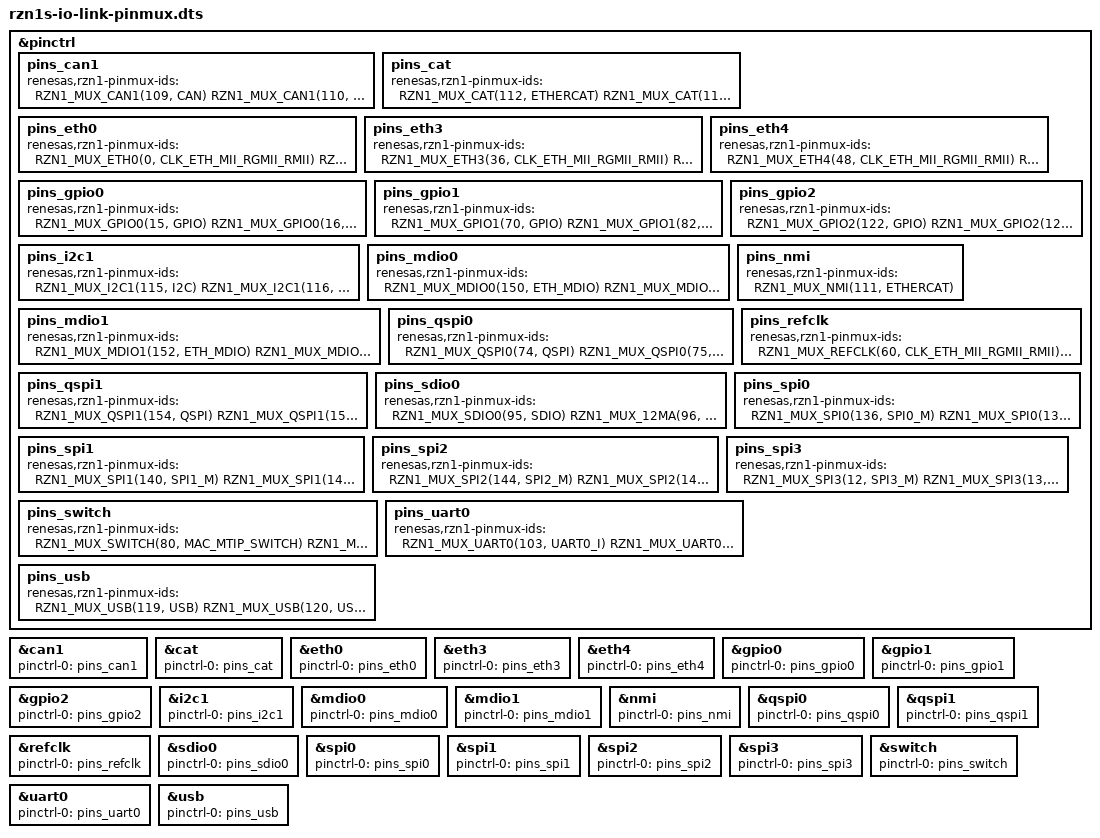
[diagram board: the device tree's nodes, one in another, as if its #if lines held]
/*
 * This file was autogenerated
 * DO NOT EDIT
 * (C) 2015-2016 Renesas Electronics Europe, LTD
 * All rights reserved.
 *
 * Redistribution and use in source and binary forms, with or without
 * modification, are permitted provided that the following conditions are met:
 *
 * 1. Redistributions of source code must retain the above copyright notice,
 * this list of conditions and the following disclaimer.
 *
 * 2. Redistributions in binary form must reproduce the above copyright notice,
 * this list of conditions and the following disclaimer in the documentation
 * and/or other materials provided with the distribution.
 *
 * THIS SOFTWARE IS PROVIDED BY THE COPYRIGHT HOLDERS AND CONTRIBUTORS "AS IS"
 * AND ANY EXPRESS OR IMPLIED WARRANTIES, INCLUDING, BUT NOT LIMITED TO, THE
 * IMPLIED WARRANTIES OF MERCHANTABILITY AND FITNESS FOR A PARTICULAR PURPOSE
 * ARE DISCLAIMED. IN NO EVENT SHALL THE COPYRIGHT HOLDER OR CONTRIBUTORS BE
 * LIABLE FOR ANY DIRECT, INDIRECT, INCIDENTAL, SPECIAL, EXEMPLARY, OR
 * CONSEQUENTIAL DAMAGES (INCLUDING, BUT NOT LIMITED TO, PROCUREMENT OF
 * SUBSTITUTE GOODS OR SERVICES; LOSS OF USE, DATA, OR PROFITS; OR BUSINESS
 * INTERRUPTION) HOWEVER CAUSED AND ON ANY THEORY OF LIABILITY, WHETHER IN
 * CONTRACT, STRICT LIABILITY, OR TORT (INCLUDING NEGLIGENCE OR OTHERWISE)
 * ARISING IN ANY WAY OUT OF THE USE OF THIS SOFTWARE, EVEN IF ADVISED OF THE
 * POSSIBILITY OF SUCH DAMAGE.
 */

#include "rzn1.dtsi"

/*
 * AUTOGENERATED DO NOT EDIT
 *
 * Renesas RZ/N1S IO Link Board
 * This file only sets the pin function by default.
 *
 * You can override the default mux pullup/down and drive by
 * defining the following macros in the board file before
 * including this.
 */

#ifndef RZN1_MUX_DEFAULT
#define RZN1_MUX_DEFAULT RZN1_MUX
#endif

#ifndef RZN1_MUX_CAN
#define RZN1_MUX_CAN RZN1_MUX_DEFAULT
#endif
#ifndef RZN1_MUX_CAN1
#define RZN1_MUX_CAN1 RZN1_MUX_CAN
#endif
#ifndef RZN1_MUX_CAT
#define RZN1_MUX_CAT RZN1_MUX_DEFAULT
#endif
#ifndef RZN1_MUX_ETH0
#define RZN1_MUX_ETH0 RZN1_MUX_PNONE_6MA
#endif
#ifndef RZN1_MUX_ETH3
#define RZN1_MUX_ETH3 RZN1_MUX_PNONE_6MA
#endif
#ifndef RZN1_MUX_ETH4
#define RZN1_MUX_ETH4 RZN1_MUX_PNONE_6MA
#endif
#ifndef RZN1_MUX_GPIO
#define RZN1_MUX_GPIO RZN1_MUX_DEFAULT
#endif
#ifndef RZN1_MUX_GPIO0
#define RZN1_MUX_GPIO0 RZN1_MUX_GPIO
#endif
#ifndef RZN1_MUX_GPIO1
#define RZN1_MUX_GPIO1 RZN1_MUX_GPIO
#endif
#ifndef RZN1_MUX_GPIO2
#define RZN1_MUX_GPIO2 RZN1_MUX_GPIO
#endif
#ifndef RZN1_MUX_I2C1
#define RZN1_MUX_I2C1 RZN1_MUX_12MA
#endif
#ifndef RZN1_MUX_MDIO
#define RZN1_MUX_MDIO RZN1_MUX_DEFAULT
#endif
#ifndef RZN1_MUX_MDIO0
#define RZN1_MUX_MDIO0 RZN1_MUX_MDIO
#endif
#ifndef RZN1_MUX_MDIO1
#define RZN1_MUX_MDIO1 RZN1_MUX_MDIO
#endif
#ifndef RZN1_MUX_NMI
#define RZN1_MUX_NMI RZN1_MUX_DEFAULT
#endif
#ifndef RZN1_MUX_QSPI
#define RZN1_MUX_QSPI RZN1_MUX_DEFAULT
#endif
#ifndef RZN1_MUX_QSPI0
#define RZN1_MUX_QSPI0 RZN1_MUX_QSPI
#endif
#ifndef RZN1_MUX_QSPI1
#define RZN1_MUX_QSPI1 RZN1_MUX_QSPI
#endif
#ifndef RZN1_MUX_REFCLK
#define RZN1_MUX_REFCLK RZN1_MUX_PNONE_6MA
#endif
#ifndef RZN1_MUX_SDIO
#define RZN1_MUX_SDIO RZN1_MUX_DEFAULT
#endif
#ifndef RZN1_MUX_SDIO0
#define RZN1_MUX_SDIO0 RZN1_MUX_SDIO
#endif
#ifndef RZN1_MUX_SPI
#define RZN1_MUX_SPI RZN1_MUX_DEFAULT
#endif
#ifndef RZN1_MUX_SPI0
#define RZN1_MUX_SPI0 RZN1_MUX_SPI
#endif
#ifndef RZN1_MUX_SPI1
#define RZN1_MUX_SPI1 RZN1_MUX_SPI
#endif
#ifndef RZN1_MUX_SPI2
#define RZN1_MUX_SPI2 RZN1_MUX_SPI
#endif
#ifndef RZN1_MUX_SPI3
#define RZN1_MUX_SPI3 RZN1_MUX_SPI
#endif
#ifndef RZN1_MUX_SWITCH
#define RZN1_MUX_SWITCH RZN1_MUX_DEFAULT
#endif
#ifndef RZN1_MUX_UART
#define RZN1_MUX_UART RZN1_MUX_DEFAULT
#endif
#ifndef RZN1_MUX_UART0
#define RZN1_MUX_UART0 RZN1_MUX_UART
#endif
#ifndef RZN1_MUX_USB
#define RZN1_MUX_USB RZN1_MUX_DEFAULT
#endif

&pinctrl {
	pins_can1: pins_can1 {
		renesas,rzn1-pinmux-ids = <
			RZN1_MUX_CAN1(109, CAN)		/* CAN1_TXD */
			RZN1_MUX_CAN1(110, CAN)		/* CAN1_RXD */
		>;
	};
	pins_cat: pins_cat {
		renesas,rzn1-pinmux-ids = <
			RZN1_MUX_CAT(112, ETHERCAT)	/* CAT_I2CDATA */
			RZN1_MUX_CAT(113, ETHERCAT)	/* CAT_I2CCLK */
		>;
	};
	pins_eth0: pins_eth0 {
		renesas,rzn1-pinmux-ids = <
			RZN1_MUX_ETH0(0, CLK_ETH_MII_RGMII_RMII)	/* ETH0_TXCLK */
			RZN1_MUX_ETH0(1, CLK_ETH_MII_RGMII_RMII)	/* ETH0_TXD[0] */
			RZN1_MUX_ETH0(2, CLK_ETH_MII_RGMII_RMII)	/* ETH0_TXD[1] */
			RZN1_MUX_ETH0(3, CLK_ETH_MII_RGMII_RMII)	/* ETH0_TXD[2] */
			RZN1_MUX_ETH0(4, CLK_ETH_MII_RGMII_RMII)	/* ETH0_TXD[3] */
			RZN1_MUX_ETH0(5, CLK_ETH_MII_RGMII_RMII)	/* ETH0_TXEN */
			RZN1_MUX_ETH0(6, CLK_ETH_MII_RGMII_RMII)	/* ETH0_RXCLK */
			RZN1_MUX_ETH0(7, CLK_ETH_MII_RGMII_RMII)	/* ETH0_RXD[0] */
			RZN1_MUX_ETH0(8, CLK_ETH_MII_RGMII_RMII)	/* ETH0_RXD[1] */
			RZN1_MUX_ETH0(9, CLK_ETH_MII_RGMII_RMII)	/* ETH0_RXD[2] */
			RZN1_MUX_ETH0(10, CLK_ETH_MII_RGMII_RMII)	/* ETH0_RXD[3] */
			RZN1_MUX_ETH0(11, CLK_ETH_MII_RGMII_RMII)	/* ETH0_RXDV */
		>;
	};
	pins_eth3: pins_eth3 {
		renesas,rzn1-pinmux-ids = <
			RZN1_MUX_ETH3(36, CLK_ETH_MII_RGMII_RMII)	/* ETH3_TXCLK */
			RZN1_MUX_ETH3(37, CLK_ETH_MII_RGMII_RMII)	/* ETH3_TXD[0] */
			RZN1_MUX_ETH3(38, CLK_ETH_MII_RGMII_RMII)	/* ETH3_TXD[1] */
			RZN1_MUX_ETH3(39, CLK_ETH_MII_RGMII_RMII)	/* ETH3_TXD[2] */
			RZN1_MUX_ETH3(40, CLK_ETH_MII_RGMII_RMII)	/* ETH3_TXD[3] */
			RZN1_MUX_ETH3(41, CLK_ETH_MII_RGMII_RMII)	/* ETH3_TXEN */
			RZN1_MUX_ETH3(42, CLK_ETH_MII_RGMII_RMII)	/* ETH3_RXCLK */
			RZN1_MUX_ETH3(43, CLK_ETH_MII_RGMII_RMII)	/* ETH3_RXD[0] */
			RZN1_MUX_ETH3(44, CLK_ETH_MII_RGMII_RMII)	/* ETH3_RXD[1] */
			RZN1_MUX_ETH3(45, CLK_ETH_MII_RGMII_RMII)	/* ETH3_RXD[2] */
			RZN1_MUX_ETH3(46, CLK_ETH_MII_RGMII_RMII)	/* ETH3_RXD[3] */
			RZN1_MUX_ETH3(47, CLK_ETH_MII_RGMII_RMII)	/* ETH3_RXDV */
			RZN1_MUX_ETH3(67, CLK_ETH_MII_RGMII_RMII)	/* ETH3_RXER */
			RZN1_MUX_ETH3(68, CLK_ETH_MII_RGMII_RMII)	/* ETH3_CRS */
			RZN1_MUX_ETH3(69, CLK_ETH_MII_RGMII_RMII)	/* ETH3_COL */
		>;
	};
	pins_eth4: pins_eth4 {
		renesas,rzn1-pinmux-ids = <
			RZN1_MUX_ETH4(48, CLK_ETH_MII_RGMII_RMII)	/* ETH4_TXCLK */
			RZN1_MUX_ETH4(49, CLK_ETH_MII_RGMII_RMII)	/* ETH4_TXD[0] */
			RZN1_MUX_ETH4(50, CLK_ETH_MII_RGMII_RMII)	/* ETH4_TXD[1] */
			RZN1_MUX_ETH4(51, CLK_ETH_MII_RGMII_RMII)	/* ETH4_TXD[2] */
			RZN1_MUX_ETH4(52, CLK_ETH_MII_RGMII_RMII)	/* ETH4_TXD[3] */
			RZN1_MUX_ETH4(53, CLK_ETH_MII_RGMII_RMII)	/* ETH4_TXEN */
			RZN1_MUX_ETH4(54, CLK_ETH_MII_RGMII_RMII)	/* ETH4_RXCLK */
			RZN1_MUX_ETH4(55, CLK_ETH_MII_RGMII_RMII)	/* ETH4_RXD[0] */
			RZN1_MUX_ETH4(56, CLK_ETH_MII_RGMII_RMII)	/* ETH4_RXD[1] */
			RZN1_MUX_ETH4(57, CLK_ETH_MII_RGMII_RMII)	/* ETH4_RXD[2] */
			RZN1_MUX_ETH4(58, CLK_ETH_MII_RGMII_RMII)	/* ETH4_RXD[3] */
			RZN1_MUX_ETH4(59, CLK_ETH_MII_RGMII_RMII)	/* ETH4_RXDV */
			RZN1_MUX_ETH4(71, CLK_ETH_MII_RGMII_RMII)	/* ETH4_RXER */
			RZN1_MUX_ETH4(72, CLK_ETH_MII_RGMII_RMII)	/* ETH4_CRS */
			RZN1_MUX_ETH4(73, CLK_ETH_MII_RGMII_RMII)	/* ETH4_COL */
		>;
	};
	pins_gpio0: pins_gpio0 {
		renesas,rzn1-pinmux-ids = <
			RZN1_MUX_GPIO0(15, GPIO)	/* GPIO0A[6] */
			RZN1_MUX_GPIO0(16, GPIO)	/* GPIO0A[7] */
			RZN1_MUX_GPIO0(19, GPIO)	/* GPIO0B[11] */
			RZN1_MUX_GPIO0(20, GPIO)	/* GPIO0B[12] */
			RZN1_MUX_GPIO0(21, GPIO)	/* GPIO0A[8] */
			RZN1_MUX_GPIO0(22, GPIO)	/* GPIO0A[9] */
			RZN1_MUX_GPIO0(23, GPIO)	/* GPIO0B[13] */
			RZN1_MUX_GPIO0(24, GPIO)	/* GPIO0A[10] */
			RZN1_MUX_GPIO0(25, GPIO)	/* GPIO0B[14] */
			RZN1_MUX_GPIO0(26, GPIO)	/* GPIO0B[15] */
			RZN1_MUX_GPIO0(27, GPIO)	/* GPIO0A[11] */
			RZN1_MUX_GPIO0(28, GPIO)	/* GPIO0A[12] */
			RZN1_MUX_GPIO0(33, GPIO)	/* GPIO0A[13] */
			RZN1_MUX_GPIO0(34, GPIO)	/* GPIO0A[14] */
			RZN1_MUX_GPIO0(35, GPIO)	/* GPIO0B[20] */
			RZN1_MUX_GPIO0(62, GPIO)	/* GPIO0A[25] */
			RZN1_MUX_GPIO0(63, GPIO)	/* GPIO0A[26] */
			RZN1_MUX_GPIO0(64, GPIO)	/* GPIO0A[27] */
			RZN1_MUX_GPIO0(65, GPIO)	/* GPIO0A[28] */
			RZN1_MUX_GPIO0(66, GPIO)	/* GPIO0A[29] */
		>;
	};
	pins_gpio1: pins_gpio1 {
		renesas,rzn1-pinmux-ids = <
			RZN1_MUX_GPIO1(70, GPIO)	/* GPIO1A[1] */
			RZN1_MUX_GPIO1(82, GPIO)	/* GPIO1B[13] */
			RZN1_MUX_GPIO1(83, GPIO)	/* GPIO1B[14] */
			RZN1_MUX_GPIO1(84, GPIO)	/* GPIO1B[15] */
			RZN1_MUX_GPIO1(85, GPIO)	/* GPIO1B[16] */
			RZN1_MUX_GPIO1(86, GPIO)	/* GPIO1B[17] */
			RZN1_MUX_GPIO1(87, GPIO)	/* GPIO1B[18] */
			RZN1_MUX_GPIO1(88, GPIO)	/* GPIO1B[19] */
			RZN1_MUX_GPIO1(89, GPIO)	/* GPIO1B[20] */
			RZN1_MUX_GPIO1(90, GPIO)	/* GPIO1B[21] */
			RZN1_MUX_GPIO1(91, GPIO)	/* GPIO1B[22] */
			RZN1_MUX_GPIO1(92, GPIO)	/* GPIO1B[23] */
			RZN1_MUX_GPIO1(93, GPIO)	/* GPIO1B[24] */
			RZN1_MUX_GPIO1(94, GPIO)	/* Eth PHY Reset (GPIO1B[25]) */
			RZN1_MUX_GPIO1(105, GPIO)	/* GPIO1A[15] */
			RZN1_MUX_GPIO1(106, GPIO)	/* GPIO1A[16] */
			RZN1_MUX_GPIO1(117, GPIO)	/* GPIO1A[27] */
			RZN1_MUX_GPIO1(118, GPIO)	/* Eth3 IRQ (GPIO1A[28]) */
			RZN1_MUX_GPIO1(121, GPIO)	/* GPIO1A[31] */
		>;
	};
	pins_gpio2: pins_gpio2 {
		renesas,rzn1-pinmux-ids = <
			RZN1_MUX_GPIO2(122, GPIO)	/* GPIO2A[0] */
			RZN1_MUX_GPIO2(123, GPIO)	/* GPIO2A[1] */
			RZN1_MUX_GPIO2(124, GPIO)	/* GPIO2A[2] */
			RZN1_MUX_GPIO2(125, GPIO)	/* GPIO2A[3] */
			RZN1_MUX_GPIO2(126, GPIO)	/* Eth2 IRQ (GPIO2A[4]) */
			RZN1_MUX_GPIO2(127, GPIO)	/* GPIO2A[5] */
			RZN1_MUX_GPIO2(128, GPIO)	/* GPIO2A[6] */
			RZN1_MUX_GPIO2(129, GPIO)	/* GPIO2A[7] */
			RZN1_MUX_GPIO2(130, GPIO)	/* GPIO2A[8] */
			RZN1_MUX_GPIO2(131, GPIO)	/* GPIO2A[9] */
			RZN1_MUX_GPIO2(132, GPIO)	/* GPIO2A[10] */
			RZN1_MUX_GPIO2(133, GPIO)	/* GPIO2A[11] */
			RZN1_MUX_GPIO2(148, GPIO)	/* Touch IRQ (GPIO2A[26]) */
			RZN1_MUX_GPIO2(149, GPIO)	/* Eth5 IRQ (GPIO2A[27]) */
		>;
	};
	pins_i2c1: pins_i2c1 {
		renesas,rzn1-pinmux-ids = <
			RZN1_MUX_I2C1(115, I2C)		/* I2C1_SCL */
			RZN1_MUX_I2C1(116, I2C)		/* I2C1_SDA */
		>;
	};
	pins_mdio0: pins_mdio0 {
		renesas,rzn1-pinmux-ids = <
			RZN1_MUX_MDIO0(150, ETH_MDIO)	/* MDIO0_MDC */
			RZN1_MUX_MDIO0(151, ETH_MDIO)	/* MDIO0_MDIO */
			RZN1_MUX_MDIO0(170, MDIO_MUX_MAC0)	/* MDIO0_MUX_MAC0 */
		>;
	};
	pins_mdio1: pins_mdio1 {
		renesas,rzn1-pinmux-ids = <
			RZN1_MUX_MDIO1(152, ETH_MDIO)	/* MDIO1_MDC */
			RZN1_MUX_MDIO1(153, ETH_MDIO)	/* MDIO1_MDIO */
			RZN1_MUX_MDIO1(171, MDIO_MUX_SWITCH)	/* MDIO1_MUX_SWITCH */
		>;
	};
	pins_nmi: pins_nmi {
		renesas,rzn1-pinmux-ids = <
			RZN1_MUX_NMI(111, ETHERCAT)	/* NMI_CORTEXM[3] */
		>;
	};
	pins_qspi0: pins_qspi0 {
		renesas,rzn1-pinmux-ids = <
			RZN1_MUX_QSPI0(74, QSPI)	/* QSPI0_CS_N[0] */
			RZN1_MUX_QSPI0(75, QSPI)	/* QSPI0_IO[3] */
			RZN1_MUX_QSPI0(76, QSPI)	/* QSPI0_IO[2] */
			RZN1_MUX_QSPI0(77, QSPI)	/* QSPI0_IO[1] */
			RZN1_MUX_QSPI0(78, QSPI)	/* QSPI0_IO[0] */
			RZN1_MUX_QSPI0(79, QSPI)	/* QSPI0_CLK */
		>;
	};
	pins_qspi1: pins_qspi1 {
		renesas,rzn1-pinmux-ids = <
			RZN1_MUX_QSPI1(154, QSPI)	/* QSPI1_CS_N[0] */
			RZN1_MUX_QSPI1(155, QSPI)	/* QSPI1_IO[3] */
			RZN1_MUX_QSPI1(156, QSPI)	/* QSPI1_IO[2] */
			RZN1_MUX_QSPI1(157, QSPI)	/* QSPI1_IO[1] */
			RZN1_MUX_QSPI1(158, QSPI)	/* QSPI1_IO[0] */
			RZN1_MUX_QSPI1(159, QSPI)	/* QSPI1_CLK */
		>;
	};
	pins_refclk: pins_refclk {
		renesas,rzn1-pinmux-ids = <
			RZN1_MUX_REFCLK(60, CLK_ETH_MII_RGMII_RMII)	/* REFCLK_RGMII */
			RZN1_MUX_REFCLK(61, CLK_ETH_NAND)	/* REFCLK_MII[1] */
		>;
	};
	pins_sdio0: pins_sdio0 {
		renesas,rzn1-pinmux-ids = <
			RZN1_MUX_SDIO0(95, SDIO)	/* SDIO0_CMD */
			RZN1_MUX_12MA(96, SDIO)		/* SDIO0_CLK */
			RZN1_MUX_SDIO0(97, SDIO)	/* SDIO0_IO[0] */
			RZN1_MUX_SDIO0(98, SDIO)	/* SDIO0_IO[1] */
			RZN1_MUX_SDIO0(99, SDIO)	/* SDIO0_IO[2] */
			RZN1_MUX_SDIO0(100, SDIO)	/* SDIO0_IO[3] */
			RZN1_MUX_SDIO0(101, SDIO_E)	/* SDIO0_CD_N */
			RZN1_MUX_SDIO0(102, SDIO_E)	/* SDIO0_WP */
		>;
	};
	pins_spi0: pins_spi0 {
		renesas,rzn1-pinmux-ids = <
			RZN1_MUX_SPI0(136, SPI0_M)	/* SPI0_CLK */
			RZN1_MUX_SPI0(137, SPI0_M)	/* SPI0_MOSI */
			RZN1_MUX_SPI0(138, SPI0_M)	/* SPI0_MISO */
			RZN1_MUX_SPI0(139, SPI0_M)	/* SPI0_SS_N[0] */
		>;
	};
	pins_spi1: pins_spi1 {
		renesas,rzn1-pinmux-ids = <
			RZN1_MUX_SPI1(140, SPI1_M)	/* SPI1_CLK */
			RZN1_MUX_SPI1(141, SPI1_M)	/* SPI1_MOSI */
			RZN1_MUX_SPI1(142, SPI1_M)	/* SPI1_MISO */
			RZN1_MUX_SPI1(143, SPI1_M)	/* SPI1_SS_N[0] */
		>;
	};
	pins_spi2: pins_spi2 {
		renesas,rzn1-pinmux-ids = <
			RZN1_MUX_SPI2(144, SPI2_M)	/* SPI2_CLK */
			RZN1_MUX_SPI2(145, SPI2_M)	/* SPI2_MOSI */
			RZN1_MUX_SPI2(146, SPI2_M)	/* SPI2_MISO */
			RZN1_MUX_SPI2(147, SPI2_M)	/* SPI2_SS_N[0] */
		>;
	};
	pins_spi3: pins_spi3 {
		renesas,rzn1-pinmux-ids = <
			RZN1_MUX_SPI3(12, SPI3_M)	/* SPI3_CLK */
			RZN1_MUX_SPI3(13, SPI3_M)	/* SPI3_MOSI */
			RZN1_MUX_SPI3(14, SPI3_M)	/* SPI3_MISO */
			RZN1_MUX_SPI3(32, SPI3_M)	/* SPI3_SS_N[0] */
		>;
	};
	pins_switch: pins_switch {
		renesas,rzn1-pinmux-ids = <
			RZN1_MUX_SWITCH(80, MAC_MTIP_SWITCH)	/* SWITCH_MII_LINK[5] */
			RZN1_MUX_SWITCH(81, MAC_MTIP_SWITCH)	/* SWITCH_MII_LINK[4] */
		>;
	};
	pins_uart0: pins_uart0 {
		renesas,rzn1-pinmux-ids = <
			RZN1_MUX_UART0(103, UART0_I)	/* UART0_TXD */
			RZN1_MUX_UART0(104, UART0_I)	/* UART0_RXD */
		>;
	};
	pins_usb: pins_usb {
		renesas,rzn1-pinmux-ids = <
			RZN1_MUX_USB(119, USB)		/* USB_PPON[1] */
			RZN1_MUX_USB(120, USB)		/* USB_OC[1] */
		>;
	};
};

&can1 {
	pinctrl-names = "default";
	pinctrl-0 = <&pins_can1>;
};
&cat {
	pinctrl-names = "default";
	pinctrl-0 = <&pins_cat>;
};
&eth0 {
	pinctrl-names = "default";
	pinctrl-0 = <&pins_eth0>;
};
&eth3 {
	pinctrl-names = "default";
	pinctrl-0 = <&pins_eth3>;
};
&eth4 {
	pinctrl-names = "default";
	pinctrl-0 = <&pins_eth4>;
};
&gpio0 {
	pinctrl-names = "default";
	pinctrl-0 = <&pins_gpio0>;
};
&gpio1 {
	pinctrl-names = "default";
	pinctrl-0 = <&pins_gpio1>;
};
&gpio2 {
	pinctrl-names = "default";
	pinctrl-0 = <&pins_gpio2>;
};
&i2c1 {
	pinctrl-names = "default";
	pinctrl-0 = <&pins_i2c1>;
};
&mdio0 {
	pinctrl-names = "default";
	pinctrl-0 = <&pins_mdio0>;
};
&mdio1 {
	pinctrl-names = "default";
	pinctrl-0 = <&pins_mdio1>;
};
&nmi {
	pinctrl-names = "default";
	pinctrl-0 = <&pins_nmi>;
};
&qspi0 {
	pinctrl-names = "default";
	pinctrl-0 = <&pins_qspi0>;
};
&qspi1 {
	pinctrl-names = "default";
	pinctrl-0 = <&pins_qspi1>;
};
&refclk {
	pinctrl-names = "default";
	pinctrl-0 = <&pins_refclk>;
};
&sdio0 {
	pinctrl-names = "default";
	pinctrl-0 = <&pins_sdio0>;
};
&spi0 {
	pinctrl-names = "default";
	pinctrl-0 = <&pins_spi0>;
};
&spi1 {
	pinctrl-names = "default";
	pinctrl-0 = <&pins_spi1>;
};
&spi2 {
	pinctrl-names = "default";
	pinctrl-0 = <&pins_spi2>;
};
&spi3 {
	pinctrl-names = "default";
	pinctrl-0 = <&pins_spi3>;
};
&switch {
	pinctrl-names = "default";
	pinctrl-0 = <&pins_switch>;
};
&uart0 {
	pinctrl-names = "default";
	pinctrl-0 = <&pins_uart0>;
};
&usb {
	pinctrl-names = "default";
	pinctrl-0 = <&pins_usb>;
};

/*
 * This is the compressed Renesas Pinmux Web App data structure; this is
 * used to allow uploading this file back into the web app, make some
 * more changes and generate/save the DTS again. It is not used by Linux
 * in any way.
 */
#ifdef JSON_PRESET
N4IgdghgtgpiBcIBKMwwM4XQAiQLQHoA5ARgGVsBJAeWwBkBLMAa2wCEB7CAJwBMQANCAAOEAMbMIAcziJeAZgBMAFkEiY3BsIAW
GiABt0CANogAwgEEiitZYAqagKJ2AEiSevVQ5y4CsagHEABRp3IWCaG3CQ6nk1SkUzKJAAWQARULV0yLUiFMo1AEUyELCQYpDkpE
cAMTM6AGk1MgzqMpLKdsrmkLihDq8QMgB1SjszFzUAVQskOzKpsjYQAF0hKWEGDgB9SFgjeFAAThtERwAXbXkqJEK1EkV3M8vsIJ
cATVwMGHP7pQQQBdtIobnchCRfKdAZcSNhQfdfHFntplPDwb5VIg7BwAK5ibRokAQ/zI3zwgC+602HAOxgA7BiSHSAGwCBnKJl0t
mMukADm5HLpRwFJF5AAYRbySJLFJL5JLlJLfJLWezRVzlL5fOKBJrtdK9bzZcoWfIDabZfIlEcuVbFEd+SbmfJlU75Ky3RrTY7Tc
KncoJf7zczlMaWcp5f7FVb5GLhTGSBKEwbfMyxYHw36Wb4M8zfNL2Y9ZYWSPKS4qS8qS6qMY8uSX+SXhYXFBKWwXa4pi52y52K52
q52a6HFPXO43O83a7GBYozbOlAve6H5P2V4OV8PlEdIyy+bq91nmTqnVKD8fu6GI7PlGuVK6Wbzhyox1eJ1f4/In6yrU/bV/jwEX
9mU/Xk6STL86WlfMxRUAQYMUB8QJ9ECs3AjNwPNcCw3A3dwMVE1wIfcCPTpcCvXAn1wLQxMgI5a9t0UXkjh/ejlVXEhlFYzjbXo/
l3RIG0gOZQT+N5HN5S/HMCLIx4DzpLtdUTZkNWUn0HXNB1LVTI52J0n8dK5HNUOVYyjhY+SrUs6NkMk5CZLpeQKK/Sy0IDeSOQ8n
CGLI28POIriPIo5QqO3OiI34295D9DlANvEgQN1QVA0FA0uN5Aj0tddKPXSjVIXTXUCpTVtjQKvCQ3kvNhJzS08zFOzpJqsV2Oiw
KrSOE0gLa/i2s/XSIN06CEsUVktUeEgVnJIA
#endif
